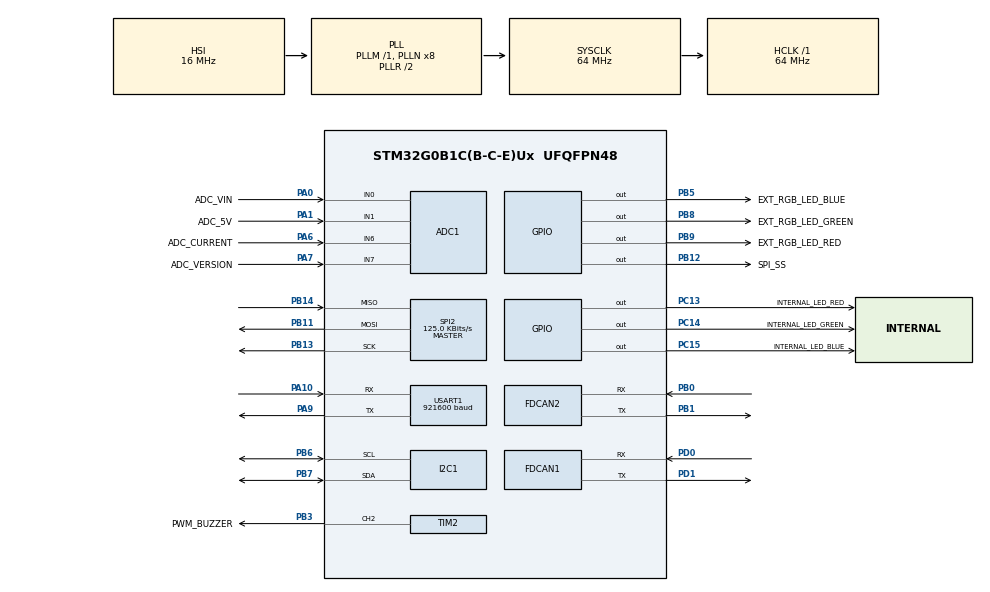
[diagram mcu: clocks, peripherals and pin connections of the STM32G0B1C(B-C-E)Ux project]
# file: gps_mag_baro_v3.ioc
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ADC1.Channel-0\#ChannelRegularConversion=ADC_CHANNEL_0
ADC1.Channel-1\#ChannelRegularConversion=ADC_CHANNEL_1
ADC1.Channel-2\#ChannelRegularConversion=ADC_CHANNEL_6
ADC1.Channel-3\#ChannelRegularConversion=ADC_CHANNEL_7
ADC1.Channel-4\#ChannelRegularConversion=ADC_CHANNEL_TEMPSENSOR
ADC1.NbrOfConversion=5
ADC1.NbrOfConversionFlag=1
ADC1.Rank-0\#ChannelRegularConversion=1
ADC1.Rank-1\#ChannelRegularConversion=2
ADC1.Rank-2\#ChannelRegularConversion=3
ADC1.Rank-3\#ChannelRegularConversion=4
ADC1.Rank-4\#ChannelRegularConversion=5
ADC1.SamplingTime-0\#ChannelRegularConversion=ADC_SAMPLINGTIME_COMMON_1
ADC1.SamplingTime-1\#ChannelRegularConversion=ADC_SAMPLINGTIME_COMMON_1
ADC1.SamplingTime-2\#ChannelRegularConversion=ADC_SAMPLINGTIME_COMMON_1
ADC1.SamplingTime-3\#ChannelRegularConversion=ADC_SAMPLINGTIME_COMMON_1
ADC1.SamplingTime-4\#ChannelRegularConversion=ADC_SAMPLINGTIME_COMMON_1
ADC1.SamplingTimeCommon1=ADC_SAMPLETIME_79CYCLES_5
ADC1.SamplingTimeCommon2=ADC_SAMPLETIME_79CYCLES_5
ADC1.SelectedChannel=ADC_CHANNEL_0|ADC_CHANNEL_1|ADC_CHANNEL_6|ADC_CHANNEL_7|ADC_CHANNEL_TEMPSENSOR
ADC1.master=1
Dma.ADC1.0.Direction=DMA_PERIPH_TO_MEMORY
Dma.ADC1.0.EventEnable=DISABLE
Dma.ADC1.0.Instance=DMA1_Channel1
Dma.ADC1.0.MemDataAlignment=DMA_MDATAALIGN_HALFWORD
Dma.ADC1.0.MemInc=DMA_MINC_ENABLE
Dma.ADC1.0.Mode=DMA_CIRCULAR
Dma.ADC1.0.PeriphDataAlignment=DMA_PDATAALIGN_HALFWORD
Dma.ADC1.0.PeriphInc=DMA_PINC_DISABLE
Dma.ADC1.0.Polarity=HAL_DMAMUX_REQ_GEN_RISING
Dma.ADC1.0.Priority=DMA_PRIORITY_LOW
Dma.ADC1.0.RequestNumber=1
Dma.ADC1.0.SignalID=NONE
Dma.ADC1.0.SyncEnable=DISABLE
Dma.ADC1.0.SyncPolarity=HAL_DMAMUX_SYNC_NO_EVENT
Dma.ADC1.0.SyncRequestNumber=1
Dma.ADC1.0.SyncSignalID=NONE
Dma.Request0=ADC1
Dma.Request1=USART1_RX
Dma.USART1_RX.1.Direction=DMA_PERIPH_TO_MEMORY
Dma.USART1_RX.1.EventEnable=DISABLE
Dma.USART1_RX.1.Instance=DMA1_Channel2
Dma.USART1_RX.1.MemDataAlignment=DMA_MDATAALIGN_BYTE
Dma.USART1_RX.1.MemInc=DMA_MINC_ENABLE
Dma.USART1_RX.1.Mode=DMA_CIRCULAR
Dma.USART1_RX.1.PeriphDataAlignment=DMA_PDATAALIGN_BYTE
Dma.USART1_RX.1.PeriphInc=DMA_PINC_DISABLE
Dma.USART1_RX.1.Polarity=HAL_DMAMUX_REQ_GEN_RISING
Dma.USART1_RX.1.Priority=DMA_PRIORITY_LOW
Dma.USART1_RX.1.RequestNumber=1
Dma.USART1_RX.1.SignalID=NONE
Dma.USART1_RX.1.SyncEnable=DISABLE
Dma.USART1_RX.1.SyncPolarity=HAL_DMAMUX_SYNC_NO_EVENT
Dma.USART1_RX.1.SyncRequestNumber=1
Dma.USART1_RX.1.SyncSignalID=NONE
FDCAN1.AutoRetransmission=ENABLE
FDCAN1.CalculateBaudRateNominal=1000000
FDCAN1.CalculateTimeBitNominal=1000
FDCAN1.CalculateTimeQuantumNominal=125.0
FDCAN1.ClockDivider=FDCAN_CLOCK_DIV1
FDCAN1.DataPrescaler=1
FDCAN1.DataTimeSeg1=1
FDCAN1.DataTimeSeg2=1
FDCAN1.ExtFiltersNbr=5
FDCAN1.FrameFormat=FDCAN_FRAME_CLASSIC
FDCAN1.Mode=FDCAN_MODE_NORMAL
FDCAN1.NominalPrescaler=4
FDCAN1.NominalSyncJumpWidth=1
FDCAN1.NominalTimeSeg1=5
FDCAN1.TransmitPause=ENABLE
FDCAN1.TxFifoQueueMode=FDCAN_TX_FIFO_OPERATION
FDCAN2.AutoRetransmission=ENABLE
FDCAN2.CalculateBaudRateNominal=1000000
FDCAN2.CalculateTimeBitNominal=1000
FDCAN2.CalculateTimeQuantumNominal=125.0
FDCAN2.ExtFiltersNbr=5
FDCAN2.NominalPrescaler=4
FDCAN2.NominalTimeSeg1=5
FDCAN2.TransmitPause=ENABLE
I2C1.Timing=0x00707CBB
IWDG.Prescaler=IWDG_PRESCALER_4
Mcu.Family=STM32G0
Mcu.Name=STM32G0B1C(B-C-E)Ux
Mcu.Package=UFQFPN48
NVIC.DMA1_Channel1_IRQn=true\:0\:0\:false\:false\:true\:false\:true\:true
NVIC.DMA1_Channel2_3_IRQn=true\:0\:0\:false\:false\:true\:false\:true\:true
NVIC.TIM16_FDCAN_IT0_IRQn=true\:0\:0\:false\:false\:true\:true\:true\:true
NVIC.TIM17_FDCAN_IT1_IRQn=true\:0\:0\:false\:false\:true\:true\:true\:true
NVIC.TIM1_BRK_UP_TRG_COM_IRQn=true\:3\:0\:false\:false\:true\:false\:true\:true
NVIC.TimeBase=TIM1_BRK_UP_TRG_COM_IRQn
NVIC.TimeBaseIP=TIM1
NVIC.USART1_IRQn=true\:0\:0\:false\:false\:true\:true\:true\:true
PA0.GPIO_Label=ADC_VIN
PA0.Mode=IN0
PA0.Signal=ADC1_IN0
PA1.GPIO_Label=ADC_5V
PA1.Mode=IN1
PA1.Signal=ADC1_IN1
PA10.Mode=Asynchronous
PA10.Signal=USART1_RX
PA13.Mode=Serial_Wire
PA13.Signal=SYS_SWDIO
PA14-BOOT0.Mode=Serial_Wire
PA14-BOOT0.Signal=SYS_SWCLK
PA6.GPIO_Label=ADC_CURRENT
PA6.Mode=IN6
PA6.Signal=ADC1_IN6
PA7.GPIO_Label=ADC_VERSION
PA7.Mode=IN7
PA7.Signal=ADC1_IN7
PA9.Mode=Asynchronous
PA9.Signal=USART1_TX
PB0.Mode=FDCAN_Activate
PB0.Signal=FDCAN2_RX
PB1.Mode=FDCAN_Activate
PB1.Signal=FDCAN2_TX
PB11.Mode=Full_Duplex_Master
PB11.Signal=SPI2_MOSI
PB12.GPIO_Label=SPI_SS
PB12.Signal=GPIO_Output
PB13.Mode=Full_Duplex_Master
PB13.Signal=SPI2_SCK
PB14.Mode=Full_Duplex_Master
PB14.Signal=SPI2_MISO
PB3.GPIO_Label=PWM_BUZZER
PB3.Signal=S_TIM2_CH2
PB5.GPIO_Label=EXT_RGB_LED_BLUE
PB5.Signal=GPIO_Output
PB6.Mode=I2C
PB6.Signal=I2C1_SCL
PB7.Mode=I2C
PB7.Signal=I2C1_SDA
PB8.GPIO_Label=EXT_RGB_LED_GREEN
PB8.Signal=GPIO_Output
PB9.GPIO_Label=EXT_RGB_LED_RED
PB9.Signal=GPIO_Output
PC13.GPIO_Label=INTERNAL_LED_RED
PC13.Signal=GPIO_Output
PC14-OSC32_IN\ (PC14).GPIO_Label=INTERNAL_LED_GREEN
PC14-OSC32_IN\ (PC14).Signal=GPIO_Output
PC15-OSC32_OUT\ (PC15).GPIO_Label=INTERNAL_LED_BLUE
PC15-OSC32_OUT\ (PC15).Signal=GPIO_Output
PD0.Mode=FDCAN_Activate
PD0.Signal=FDCAN1_RX
PD1.Mode=FDCAN_Activate
PD1.Signal=FDCAN1_TX
PF0-OSC_IN\ (PF0).Mode=HSE-External-Oscillator
PF0-OSC_IN\ (PF0).Signal=RCC_OSC_IN
PF1-OSC_OUT\ (PF1).Mode=HSE-External-Oscillator
PF1-OSC_OUT\ (PF1).Signal=RCC_OSC_OUT
ProjectManager.HeapSize=0x200
ProjectManager.StackSize=0x400
ProjectManager.TargetToolchain=Makefile
RCC.ADCFreq_Value=64000000
RCC.AHBFreq_Value=64000000
RCC.APB1CLKDivider=RCC_HCLK_DIV2
RCC.CortexFreq_Value=64000000
RCC.EXTERNAL_CLOCK_VALUE=48000
RCC.HCLKFreq_Value=64000000
RCC.HSE_VALUE=8000000
RCC.HSI48_VALUE=48000000
RCC.HSI_VALUE=16000000
RCC.LSE_VALUE=32768
RCC.SYSCLKFreq_VALUE=64000000
RCC.SYSCLKSource=RCC_SYSCLKSOURCE_PLLCLK
RCC.USBFreq_Value=48000000
RCC.VCOOutputFreq_Value=128000000
SH.S_TIM2_CH2.0=TIM2_CH2,PWM Generation2 CH2
SPI2.BaudRatePrescaler=SPI_BAUDRATEPRESCALER_256
SPI2.CalculateBaudRate=125.0 KBits/s
SPI2.Direction=SPI_DIRECTION_2LINES
SPI2.Mode=SPI_MODE_MASTER
SPI2.VirtualType=VM_MASTER
TIM2.Channel-PWM\ Generation2\ CH2=TIM_CHANNEL_2
TIM2.Period=20000
TIM2.Prescaler=63
USART1.BaudRate=921600
USART1.Mode=MODE_TX_RX
USART1.VirtualMode-Asynchronous=VM_ASYNC
VP_ADC1_TempSens_Input.Mode=IN-TempSens
VP_IWDG_VS_IWDG.Mode=IWDG_Activate
VP_SYS_VS_DBSignals.Mode=DisableDeadBatterySignals
VP_SYS_VS_tim1.Mode=TIM1
VP_TIM2_VS_ClockSourceINT.Mode=Internal
board=custom

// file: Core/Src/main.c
/* USER CODE BEGIN Header */
/**
  ******************************************************************************
  * @file           : main.c
  * @brief          : Main program body
  ******************************************************************************
  * @attention
  *
  * Copyright (c) 2023 STMicroelectronics.
  * All rights reserved.
  *
  * This software is licensed under terms that can be found in the LICENSE file
  * in the root directory of this software component.
  * If no LICENSE file comes with this software, it is provided AS-IS.
  *
  ******************************************************************************
  */
/* USER CODE END Header */
#include "main.h"
#include "adc.h"
#include "dma.h"
#include "fdcan.h"
#include "i2c.h"
#include "iwdg.h"
#include "spi.h"
#include "tim.h"
#include "usart.h"
#include "gpio.h"

/* USER CODE BEGIN Includes */
#include "application.hpp"
/* USER CODE END Includes */

void SystemClock_Config(void);

int main(void)
{

  /* MCU Configuration--------------------------------------------------------*/

  /* Reset of all peripherals, Initializes the Flash interface and the Systick. */
  HAL_Init();

  /* Configure the system clock */
  SystemClock_Config();

  /* Initialize all configured peripherals */
  MX_GPIO_Init();
  MX_DMA_Init();
  MX_FDCAN1_Init();
  MX_ADC1_Init();
  MX_I2C1_Init();
  MX_USART1_UART_Init();
  MX_SPI2_Init();
  MX_IWDG_Init();
  MX_FDCAN2_Init();
  MX_TIM2_Init();
  /* USER CODE BEGIN 2 */
  __enable_irq();
  application_entry_point();
  /* USER CODE END 2 */

  /* Infinite loop */
  while (1)
  {

  }
}

void SystemClock_Config(void)
{
  RCC_OscInitTypeDef RCC_OscInitStruct = {0};
  RCC_ClkInitTypeDef RCC_ClkInitStruct = {0};

  /** Configure the main internal regulator output voltage
  */
  HAL_PWREx_ControlVoltageScaling(PWR_REGULATOR_VOLTAGE_SCALE1);

  /** Initializes the RCC Oscillators according to the specified parameters
  * in the RCC_OscInitTypeDef structure.
  */
  RCC_OscInitStruct.OscillatorType = RCC_OSCILLATORTYPE_HSI|RCC_OSCILLATORTYPE_LSI;
  RCC_OscInitStruct.HSIState = RCC_HSI_ON;
  RCC_OscInitStruct.HSIDiv = RCC_HSI_DIV1;
  RCC_OscInitStruct.HSICalibrationValue = RCC_HSICALIBRATION_DEFAULT;
  RCC_OscInitStruct.LSIState = RCC_LSI_ON;
  RCC_OscInitStruct.PLL.PLLState = RCC_PLL_ON;
  RCC_OscInitStruct.PLL.PLLSource = RCC_PLLSOURCE_HSI;
  RCC_OscInitStruct.PLL.PLLM = RCC_PLLM_DIV1;
  RCC_OscInitStruct.PLL.PLLN = 8;
  RCC_OscInitStruct.PLL.PLLP = RCC_PLLP_DIV2;
  RCC_OscInitStruct.PLL.PLLQ = RCC_PLLQ_DIV2;
  RCC_OscInitStruct.PLL.PLLR = RCC_PLLR_DIV2;
  if (HAL_RCC_OscConfig(&RCC_OscInitStruct) != HAL_OK)
  {
    Error_Handler();
  }

  /** Initializes the CPU, AHB and APB buses clocks
  */
  RCC_ClkInitStruct.ClockType = RCC_CLOCKTYPE_HCLK|RCC_CLOCKTYPE_SYSCLK
                              |RCC_CLOCKTYPE_PCLK1;
  RCC_ClkInitStruct.SYSCLKSource = RCC_SYSCLKSOURCE_PLLCLK;
  RCC_ClkInitStruct.AHBCLKDivider = RCC_SYSCLK_DIV1;
  RCC_ClkInitStruct.APB1CLKDivider = RCC_HCLK_DIV2;

  if (HAL_RCC_ClockConfig(&RCC_ClkInitStruct, FLASH_LATENCY_2) != HAL_OK)
  {
    Error_Handler();
  }
}

void HAL_TIM_PeriodElapsedCallback(TIM_HandleTypeDef *htim)
{
  if (htim->Instance == TIM1) {
    HAL_IncTick();
  }
}

void Error_Handler(void)
{
  __disable_irq();
  while (1)
  {
  }
}
